AUTOSAR XML (schema 314)
package /ComponentType
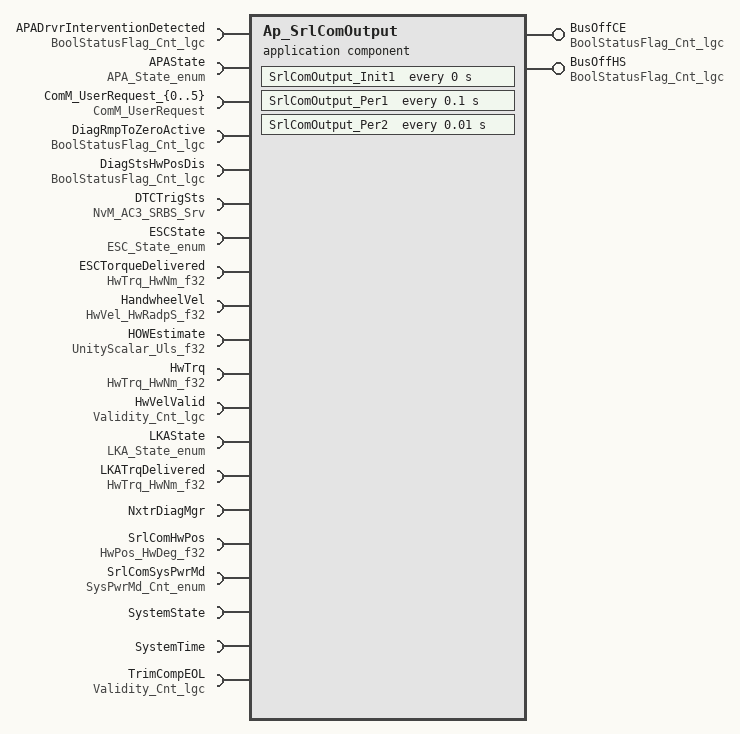
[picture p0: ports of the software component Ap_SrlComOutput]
  application software component type Ap_SrlComOutput
    provide port BusOffCE: unqueued-sender-com-spec{data-element=Cnt_lgc, can-invalidate=false, init-value=D_FALSE_CNT_LGC}, provided-interface=BoolStatusFlag_Cnt_lgc
    provide port BusOffHS: unqueued-sender-com-spec{data-element=Cnt_lgc, can-invalidate=false, init-value=D_FALSE_CNT_LGC}, provided-interface=BoolStatusFlag_Cnt_lgc
    25 x require port:
      APADrvrInterventionDetected: unqueued-receiver-com-spec{data-element=Cnt_lgc, init-value=D_FALSE_CNT_LGC}, required-interface=BoolStatusFlag_Cnt_lgc
      APAState: unqueued-receiver-com-spec{data-element=State_enum, init-value=D_APASTATEINIT_CNT_U08}, required-interface=APA_State_enum
      ComM_UserRequest_{0..5}: required-com-specs=[GetCurrentComMode, GetMaxComMode, GetRequestedComMode, RequestComMode], required-interface=ComM_UserRequest
      DiagRmpToZeroActive: unqueued-receiver-com-spec{data-element=Cnt_lgc, init-value=D_FALSE_CNT_LGC}, required-interface=BoolStatusFlag_Cnt_lgc
      DiagStsHwPosDis: unqueued-receiver-com-spec{data-element=Cnt_lgc, init-value=D_FALSE_CNT_LGC}, required-interface=BoolStatusFlag_Cnt_lgc
      DTCTrigSts: required-com-specs=[EraseBlock, GetErrorStatus, InvalidateNvBlock, ReadBlock, SetRamBlockStatus, WriteBlock], required-interface=NvM_AC3_SRBS_Srv
      ESCState: unqueued-receiver-com-spec{data-element=State_enum, init-value=D_ESCSTATEINIT_CNT_U08}, required-interface=ESC_State_enum
      ESCTorqueDelivered: unqueued-receiver-com-spec{data-element=HwNm_f32, init-value=D_ZERO_ULS_F32}, required-interface=HwTrq_HwNm_f32
      HandwheelVel: unqueued-receiver-com-spec{data-element=HwRadpS_f32, init-value=D_ZERO_ULS_F32}, required-interface=HwVel_HwRadpS_f32
      HOWEstimate: unqueued-receiver-com-spec{data-element=Uls_f32, init-value=D_ZERO_ULS_F32}, required-interface=UnityScalar_Uls_f32
      HwTrq: unqueued-receiver-com-spec{data-element=HwNm_f32, init-value=D_ZERO_ULS_F32}, required-interface=HwTrq_HwNm_f32
      HwVelValid: unqueued-receiver-com-spec{data-element=Cnt_lgc, init-value=D_FALSE_CNT_LGC}, required-interface=Validity_Cnt_lgc
      LKAState: unqueued-receiver-com-spec{data-element=State_enum, init-value=D_LKASTATEINIT_CNT_U08}, required-interface=LKA_State_enum
      LKATrqDelivered: unqueued-receiver-com-spec{data-element=HwNm_f32, init-value=D_ZERO_ULS_F32}, required-interface=HwTrq_HwNm_f32
      NxtrDiagMgr: required-com-specs=[GetNTCActive, GetNTCFailed, GetNTCStatus, SetNTCStatus], required-interface=NxtrDiagMgr
      SrlComHwPos: unqueued-receiver-com-spec{data-element=HwDeg_f32, init-value=D_ZERO_ULS_F32}, required-interface=HwPos_HwDeg_f32
      SrlComSysPwrMd: unqueued-receiver-com-spec{data-element=Cnt_enum, init-value=D_SYSPWRMODESTATEINIT_CNT_ENUM}, required-interface=SysPwrMd_Cnt_enum
      SystemState: required-interface=SystemState
      SystemTime: required-interface=SystemTime
        required-com-specs:
          DtrmnElapsedTime_mS_u16
          DtrmnElapsedTime_mS_u32
          DtrmnElapsedTime_uS_u16
          DtrmnElapsedTime_uS_u32
          GetSystemTime_mS_u32
          GetSystemTime_uS_u32
      TrimCompEOL: unqueued-receiver-com-spec{data-element=Cnt_lgc, init-value=D_FALSE_CNT_LGC}, required-interface=Validity_Cnt_lgc
  internal behavior Ap_SrlComOutput_InternalBehavior: component=Ap_SrlComOutput
    timing event SrlComOutput_Init1_InitEvent: start-on-event=SrlComOutput_Init1, period=0
    timing event TMT_SrlComOutput_Per1: mode-dependency=dependent-on-mode=SystemState.Mode.OFF, start-on-event=SrlComOutput_Per1, period=0.1
    timing event TMT_SrlComOutput_Per2: mode-dependency=dependent-on-mode=SystemState.Mode.OFF, start-on-event=SrlComOutput_Per2, period=0.01
    mode switch event MST_SrlComOutput_Trns1_0: start-on-event=SrlComOutput_Trns1, activation=ENTRY, mode=SystemState.Mode.OFF
    per instance memory DTCTrigSts: type=DTCStsFlg, type-definition=/DataType/DTCStsFlg
    port-api-options:
      enable-take-address=false, indirect-api=false, port=APADrvrInterventionDetected
      enable-take-address=false, indirect-api=false, port=APAState
      enable-take-address=false, indirect-api=false, port=BusOffCE
      enable-take-address=false, indirect-api=false, port=BusOffHS
      enable-take-address=false, indirect-api=false, port=ComM_UserRequest_{0..5}
      enable-take-address=false, indirect-api=false, port=DiagRmpToZeroActive
      enable-take-address=false, indirect-api=false, port=DiagStsHwPosDis
      enable-take-address=false, indirect-api=false, port=DTCTrigSts
      enable-take-address=false, indirect-api=false, port=ESCState
      enable-take-address=false, indirect-api=false, port=ESCTorqueDelivered
      enable-take-address=false, indirect-api=false, port=HandwheelVel
      enable-take-address=false, indirect-api=false, port=HOWEstimate
      enable-take-address=false, indirect-api=false, port=HwTrq
      enable-take-address=false, indirect-api=false, port=HwVelValid
      enable-take-address=false, indirect-api=false, port=LKAState
      enable-take-address=false, indirect-api=false, port=LKATrqDelivered
      enable-take-address=false, indirect-api=false, port=NxtrDiagMgr
      enable-take-address=false, indirect-api=false, port=SrlComHwPos
      enable-take-address=false, indirect-api=false, port=SrlComSysPwrMd
      enable-take-address=false, indirect-api=false, port=SystemState
      enable-take-address=false, indirect-api=false, port=SystemTime
      enable-take-address=false, indirect-api=false, port=TrimCompEOL
    4 x runnable:
      SrlComOutput_Init1
        6 x sync call, all with timeout=0:
          SC_ComM_UserRequest_{0..5}_RequestComMode: operation=ComM_UserRequest_{0..5}.RequestComMode
      SrlComOutput_Per1
        9 x data receive point:
          REC_APADrvrInterventionDetected_Cnt_lgc: data-element=APADrvrInterventionDetected.Cnt_lgc
          REC_APAState_State_enum: data-element=APAState.State_enum
          REC_DiagRmpToZeroActive_Cnt_lgc: data-element=DiagRmpToZeroActive.Cnt_lgc
          REC_ESCState_State_enum: data-element=ESCState.State_enum
          REC_ESCTorqueDelivered_HwNm_f32: data-element=ESCTorqueDelivered.HwNm_f32
          REC_HOWEstimate_Uls_f32: data-element=HOWEstimate.Uls_f32
          REC_HwTrq_HwNm_f32: data-element=HwTrq.HwNm_f32
          REC_LKAState_State_enum: data-element=LKAState.State_enum
          REC_LKATrqDelivered_HwNm_f32: data-element=LKATrqDelivered.HwNm_f32
        sync call SC_SystemTime_DtrmnElapsedTime_mS_u16: operation=SystemTime.DtrmnElapsedTime_mS_u16, timeout=0
        sync call SC_SystemTime_GetSystemTime_mS_u32: operation=SystemTime.GetSystemTime_mS_u32, timeout=0
      SrlComOutput_Per2
        6 x data receive point:
          REC_DiagStsHwPosDis_Cnt_lgc: data-element=DiagStsHwPosDis.Cnt_lgc
          REC_HandwheelVel_HwRadpS_f32: data-element=HandwheelVel.HwRadpS_f32
          REC_HwVelValid_Cnt_lgc: data-element=HwVelValid.Cnt_lgc
          REC_SrlComHwPos_HwDeg_f32: data-element=SrlComHwPos.HwDeg_f32
          REC_SrlComSysPwrMd_Cnt_enum: data-element=SrlComSysPwrMd.Cnt_enum
          REC_TrimCompEOL_Cnt_lgc: data-element=TrimCompEOL.Cnt_lgc
        data send point SEND_BusOffCE_Cnt_lgc: data-element=BusOffCE.Cnt_lgc
        data send point SEND_BusOffHS_Cnt_lgc: data-element=BusOffHS.Cnt_lgc
        sync call SC_NxtrDiagMgr_GetNTCActive: operation=NxtrDiagMgr.GetNTCActive, timeout=0
        sync call SC_NxtrDiagMgr_SetNTCStatus: operation=NxtrDiagMgr.SetNTCStatus, timeout=0
      SrlComOutput_Trns1
        sync call SC_DTCTrigSts_WriteBlock: operation=DTCTrigSts.WriteBlock, timeout=0
    service-needss:
      swc nv block needs DTCTriggeredStsBlk: n-data-sets=0, readonly=false, reliability=LOW, resistant-to-changed-sw=false, restore-at-start=false, write-only-once=false, writing-frequency=0, writing-priority=LOW, mirror-block=DTCTrigSts, service-call-ports=role-based-r-port-assignment={r-port-prototype=DTCTrigSts, role=NvM_AC3_SRBS_Srv}
  swc implementation Ap_SrlComOutput_Implementation: behavior=Ap_SrlComOutput_InternalBehavior
    code-descriptors:
      code Code: type=SRC
